# moondancer register map
Vendor: luna-soc
Registers are 8-bit, read-write, reset 0x0 unless marked. A register's access mark holds for its fields unless they carry their own. Offsets are from the block's base; [hi:lo] are bit positions; <NAME> marks a mode.

## spi0
Base 0xF0000700
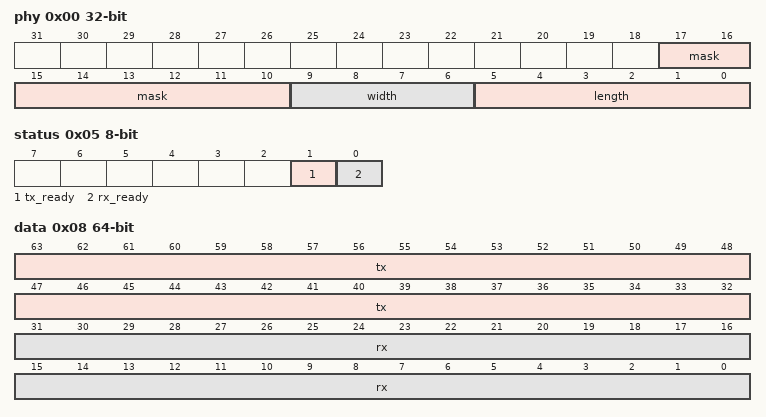
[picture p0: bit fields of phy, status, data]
0x00 phy 32-bit — PHY control register length : SPI transfer length in bits. width : SPI transfer bus width (1/2/4/8). mask : SPI DQ output enable mask.
  [17:10] mask, [9:6] width, [5:0] length
0x04 cs — SPI chip select register select : SPI chip select signal.
  [0] select wo
0x05 status — Status register rx_ready : RX FIFO contains data. tx_ready : TX FIFO ready to receive data.
  [1] tx_ready ro, [0] rx_ready ro
0x08 data 64-bit (reset mask 0xFFFFFFFF) — Data register rx : Read the next byte in the RX FIFO tx : Write the given byte to the TX FIFO
  [63:32] tx wo, [31:0] rx ro

## usb0
Base 0xF0000800
Same registers: usb1 0xF0000C00, usb2 0xF0001000
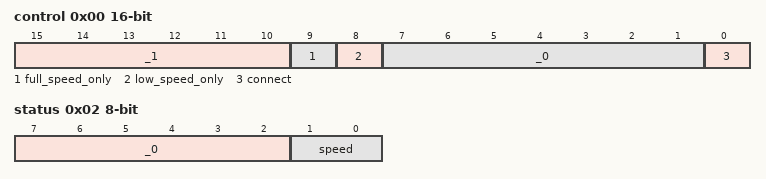
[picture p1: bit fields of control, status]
0x00 control 16-bit — Control register connect: Set this bit to '1' to allow the associated USB device to connect to a host. low_speed_only: Set this bit to '1' to force the device to operate at low speed. full_speed_only: Set this bit to '1' to force the device to operate at full speed.
  [15:10] _1, [9] full_speed_only, [8] low_speed_only, [7:1] _0, [0] connect
0x02 status — Status register speed: Indicates the current speed of the USB device. 0 indicates High; 1 => Full, 2 => Low, and 3 => SuperSpeed (incl SuperSpeed+).
  [7:2] _0, [1:0] speed ro
0x08 ev_enable — A CSR register. Parameters ---------- fields : :class:`dict` or :class:`list` or :class:`Field` Collection of register fields. If ``None`` (default), a dict is populated from Python :term:`variable annotations <python:variable annotations>`. ``fields`` is used to create a :class:`FieldActionMap`, :class:`FieldActionArray`, or :class:`FieldAction`, depending on its type (dict, list, or Field). Interface attributes -------------------- element : :class:`Element` Interface between this register and a CSR bus primitive. Attributes ---------- field : :class:`FieldActionMap` or :class:`FieldActionArray` or :class:`FieldAction` Collection of field instances. f : :class:`FieldActionMap` or :class:`FieldActionArray` or :class:`FieldAction` Shorthand for :attr:`Register.field`. Raises ------ :exc:`TypeError` If ``fields`` is neither ``None``, a :class:`dict`, a :class:`list`, or a :class:`Field`. :exc:`ValueError` If ``fields`` is not ``None`` and at least one variable annotation is a :class:`Field`. :exc:`ValueError` If ``element.access`` is not readable and at least one field is readable. :exc:`ValueError` If ``element.access`` is not writable and at least one field is writable.
  [0] mask
0x09 ev_pending — A CSR register. Parameters ---------- fields : :class:`dict` or :class:`list` or :class:`Field` Collection of register fields. If ``None`` (default), a dict is populated from Python :term:`variable annotations <python:variable annotations>`. ``fields`` is used to create a :class:`FieldActionMap`, :class:`FieldActionArray`, or :class:`FieldAction`, depending on its type (dict, list, or Field). Interface attributes -------------------- element : :class:`Element` Interface between this register and a CSR bus primitive. Attributes ---------- field : :class:`FieldActionMap` or :class:`FieldActionArray` or :class:`FieldAction` Collection of field instances. f : :class:`FieldActionMap` or :class:`FieldActionArray` or :class:`FieldAction` Shorthand for :attr:`Register.field`. Raises ------ :exc:`TypeError` If ``fields`` is neither ``None``, a :class:`dict`, a :class:`list`, or a :class:`Field`. :exc:`ValueError` If ``fields`` is not ``None`` and at least one variable annotation is a :class:`Field`. :exc:`ValueError` If ``element.access`` is not readable and at least one field is readable. :exc:`ValueError` If ``element.access`` is not writable and at least one field is writable.
  [0] mask

## advertiser
Base 0xF0001400
0x00 control — Control register enable : Set this bit to '1' to start ApolloAdvertiser and disconnect the Cynthion USB control port from Apollo.
  [0] enable wo
